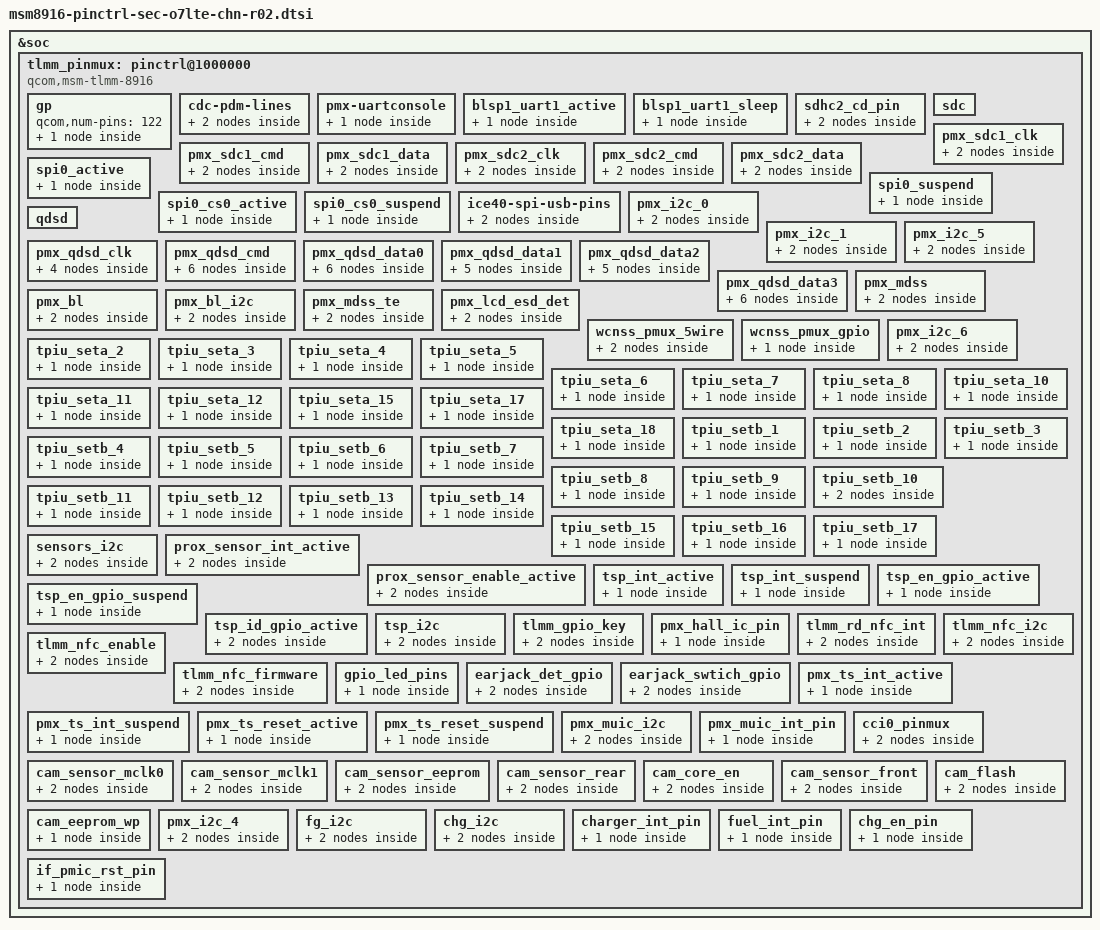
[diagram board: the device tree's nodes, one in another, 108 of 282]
/* Copyright (c) 2013-2014, The Linux Foundation. All rights reserved.
 *
 * This program is free software; you can redistribute it and/or modify
 * it under the terms of the GNU General Public License version 2 and
 * only version 2 as published by the Free Software Foundation.
 *
 * This program is distributed in the hope that it will be useful,
 * but WITHOUT ANY WARRANTY; without even the implied warranty of
 * MERCHANTABILITY or FITNESS FOR A PARTICULAR PURPOSE.  See the
 * GNU General Public License for more details.
 */

&soc {
	tlmm_pinmux: pinctrl@1000000 {
		compatible = "qcom,msm-tlmm-8916";
		reg = <0x1000000 0x300000>;
		interrupts = <0 208 0>;

		/*General purpose pins*/
		gp: gp {
			qcom,num-pins = <122>;
			#qcom,pin-cells = <1>;
			msm_gpio: msm_gpio {
				compatible = "qcom,msm-tlmm-gp";
				gpio-controller;
				#gpio-cells = <2>;
				interrupt-controller;
				#interrupt-cells = <2>;
				num_irqs = <122>;
			};
		};

		cdc-pdm-lines {
			qcom,pins = <&gp 63>, <&gp 64>, <&gp 65>,
					<&gp 66>, <&gp 67>, <&gp 68>;
			qcom,num-grp-pins = <6>;
			qcom,pin-func = <1>;
			label = "cdc-pdm-lines";
			cdc_pdm_lines_act: pdm_lines_on {
				drive-strength = <8>;
				bias-pull-down;
			};
			cdc_pdm_lines_sus: pdm_lines_off {
				drive-strength = <2>;
				bias-pull-down;
			};
		};
		pmx-uartconsole {
			qcom,pins = <&gp 4>, <&gp 5>;
			qcom,num-grp-pins = <2>;
			qcom,pin-func = <2>;
			label = "uart-console";

		uart_console_sleep: uart-console {
				drive-strength = <2>;
				bias-pull-down;
			};
		};

		blsp1_uart1_active {
			qcom,pins = <&gp 0>, <&gp 1>, <&gp 2>, <&gp 3>;
			qcom,num-grp-pins = <4>;
			qcom,pin-func = <2>;
		        label = "blsp1_uart1_active";

			hsuart_active: default {
				drive-strength = <16>;
				bias-disable;
			};
		};

		blsp1_uart1_sleep {
			qcom,pins = <&gp 0>, <&gp 1>, <&gp 2>, <&gp 3>;
			qcom,num-grp-pins = <4>;
			qcom,pin-func = <0>;
		        label = "blsp1_uart1_sleep";

			hsuart_sleep: sleep {
				drive-strength = <2>;
				bias-disable;
			};
		};


		sdhc2_cd_pin {
			qcom,pins = <&gp 38>;
			qcom,num-grp-pins = <1>;
			qcom,pin-func = <0>;
			label = "cd-gpio";
			sdc2_cd_on: cd_on {
				drive-strength = <2>;
				bias-disable;
			};
			sdc2_cd_off: cd_off {
				drive-strength = <2>;
				bias-disable;
			};
		};

		/* SDC pin type */
		sdc: sdc {
			qcom,pin-type-sdc;
			/* 0-2 for sdc1 4-6 for sdc2 */
			qcom,num-pins = <7>;
			/* Order of pins */
			/* SDC1: CLK -> 0, CMD -> 1, DATA -> 2 */
			/* SDC2: CLK -> 4, CMD -> 5, DATA -> 6 */
			#qcom,pin-cells = <1>;
		};

		pmx_sdc1_clk {
			qcom,pins = <&sdc 0>;
			qcom,num-grp-pins = <1>;
			label = "sdc1-clk";
			sdc1_clk_on: clk_on {
				bias-disable; /* NO pull */
				drive-strength = <16>; /* 16 MA */
			};
			sdc1_clk_off: clk_off {
				bias-disable; /* NO pull */
				drive-strength = <2>; /* 2 MA */
			};
		};

		pmx_sdc1_cmd {
			qcom,pins = <&sdc 1>;
			qcom,num-grp-pins = <1>;
			label = "sdc1-cmd";
			sdc1_cmd_on: cmd_on {
				bias-pull-up; /* pull up */
				drive-strength = <10>; /* 10 MA */
			};
			sdc1_cmd_off: cmd_off {
				bias-pull-up; /* pull up */
				drive-strength = <2>; /* 2 MA */
			};
		};

		pmx_sdc1_data {
			qcom,pins = <&sdc 2>;
			qcom,num-grp-pins = <1>;
			label = "sdc1-data";
			sdc1_data_on: data_on {
				bias-pull-up; /* pull up */
				drive-strength = <10>; /* 10 MA */
			};
			sdc1_data_off: data_off {
				bias-pull-up; /* pull up */
				drive-strength = <2>; /* 2 MA */
			};
		};

		pmx_sdc2_clk {
			qcom,pins = <&sdc 4>;
			qcom,num-grp-pins = <1>;
			label = "sdc2-clk";
			sdc2_clk_on: clk_on {
				bias-disable; /* NO pull */
				drive-strength = <16>; /* 16 MA */
			};
			sdc2_clk_off: clk_off {
				bias-disable; /* NO pull */
				drive-strength = <2>; /* 2 MA */
			};
		};

		pmx_sdc2_cmd {
			qcom,pins = <&sdc 5>;
			qcom,num-grp-pins = <1>;
			label = "sdc2-cmd";
			sdc2_cmd_on: cmd_on {
				bias-pull-up; /* pull up */
				drive-strength = <8>; /* 8 MA */
			};
			sdc2_cmd_off: cmd_off {
				bias-pull-up; /* pull up */
				drive-strength = <2>; /* 2 MA */
			};
		};

		pmx_sdc2_data {
			qcom,pins = <&sdc 6>;
			qcom,num-grp-pins = <1>;
			label = "sdc2-data";
			sdc2_data_on: data_on {
				bias-pull-up; /* pull up */
				drive-strength = <8>; /* 8 MA */
			};
			sdc2_data_off: data_off {
				bias-pull-up; /* pull up */
				drive-strength = <2>; /* 2 MA */
			};
		};

               spi0_active {
                        /* MOSI, MISO, CLK */
                        qcom,pins = <&gp 8>, <&gp 9>, <&gp 11>;
                        qcom,num-grp-pins = <3>;
                        qcom,pin-func = <1>;
                        label = "spi0-active";
                        /* active state */
                        spi0_default: default {
                                drive-strength = <12>; /* 12 MA */
                                bias-disable = <0>; /* No PULL */
                        };
                };

                spi0_suspend {
                        /* MOSI, MISO, CLK */
                        qcom,pins = <&gp 8>, <&gp 9>, <&gp 11>;
                        qcom,num-grp-pins = <3>;
                        qcom,pin-func = <0>;
                        label = "spi0-suspend";
                        /* suspended state */
                        spi0_sleep: sleep {
                                drive-strength = <2>; /* 2 MA */
                               bias-pull-down; /* pull down */
                        };
                };

                spi0_cs0_active {
                        /* CS */
                        qcom,pins = <&gp 10>;
                        qcom,num-grp-pins = <1>;
                        qcom,pin-func = <1>;
                        label = "spi0-cs0-active";
                        spi0_cs0_active: cs0_active {
                                drive-strength = <2>;
                                bias-disable = <0>;
                        };
                };

                spi0_cs0_suspend {
                        /* CS */
                        qcom,pins = <&gp 10>;
                        qcom,num-grp-pins = <1>;
                        qcom,pin-func = <0>;
                        label = "spi0-cs0-suspend";
                        spi0_cs0_sleep: cs0_sleep {
                                drive-strength = <2>;
                                bias-disable = <0>;
                        };
                };

                ice40-spi-usb-pins {
                        qcom,pins = <&gp 0>, <&gp 1>, <&gp 3>;
                        qcom,num-grp-pins = <3>;
                        qcom,pin-func = <0>;
                        label = "ice40-spi-usb-pins";

                        /* active state */
                        ice40_default: default {
                                drive-strength = <8>;
                                bias-disable;
                        };

                        /* sleep state */
                        ice40_sleep: sleep {
                                drive-strength = <2>;
                                bias-pull-down;
                        };
                };

		pmx_i2c_0 {
			/* CLK, DATA */
			qcom,pins = <&gp 7>, <&gp 6>;
			qcom,num-grp-pins = <2>;
			qcom,pin-func = <3>;
			label = "pmx_i2c_0";

			i2c_0_active: i2c_0_active {
				drive-strength = <2>; /* 2 MA */
				bias-disable;         /* No PULL */
			};

			i2c_0_sleep: i2c_0_sleep {
				drive-strength = <2>; /* 2 MA */
				bias-disable;	      /* No PULL */
			};
		};

		pmx_i2c_1 {
			/* CLK, DATA */
			qcom,pins = <&gp 3>, <&gp 2>;
			qcom,num-grp-pins = <2>;
			qcom,pin-func = <3>;
			label = "pmx_i2c_1";

			i2c_1_active: i2c_1_active {
				drive-strength = <2>; /* 2 MA */
				bias-pull-down;         /* PULL DOWN */
			};

			i2c_1_sleep: i2c_1_sleep {
				drive-strength = <2>; /* 2 MA */
				bias-pull-down;	      /* PULL DOWN */
			};
		};

		pmx_i2c_5 {
			/* CLK, DATA */
			qcom,pins = <&gp 19>, <&gp 18>;
			qcom,num-grp-pins = <2>;
			qcom,pin-func = <2>;
			label = "pmx_i2c_5";

			i2c_5_active: i2c_5_active {
				drive-strength = <2>; /* 2 MA */
				bias-disable = <0>; /* No PULL */
			};

			i2c_5_sleep: i2c_5_sleep {
				drive-strength = <2>; /* 2 MA */
				bias-disable = <0>; /* No PULL */
			};
		};

		/* QDSD pin type */
		qdsd: qdsd {
			qcom,pin-type-qdsd;
			/* 0-> clk, 1 -> cmd, 2->data0, 3->data1, 4->data2, 5->data3 */
			qcom,num-pins = <6>;

			#qcom,pin-cells = <1>;
		};

		pmx_qdsd_clk {
			qcom,pins = <&qdsd 0>;
			qcom,num-grp-pins = <1>;
			label = "qdsd-clk";
			qdsd_clk_sdcard: clk_sdcard {
				bias-disable; /* NO pull */
				drive-strength = <7>; /* 7 MA */
			};
			qdsd_clk_trace: clk_trace {
				bias-pull-down; /* pull down */
				drive-strength = <0>; /* 0 MA */
			};
			qdsd_clk_swdtrc: clk_swdtrc {
				bias-pull-down; /* pull down */
				drive-strength = <0>; /* 0 MA */
			};
			qdsd_clk_spmi: clk_spmi {
				bias-pull-down; /* pull down */
				drive-strength = <0>; /* 0 MA */
			};
		};

		pmx_qdsd_cmd {
			qcom,pins = <&qdsd 1>;
			qcom,num-grp-pins = <1>;
			label = "qdsd-cmd";
			qdsd_cmd_sdcard: cmd_sdcard {
				bias-pull-down; /* pull down */
				drive-strength = <3>; /* 3 MA */
			};
			qdsd_cmd_trace: cmd_trace {
				bias-pull-down; /* pull down */
				drive-strength = <0>; /* 0 MA */
			};
			qdsd_cmd_swduart: cmd_uart {
				bias-pull-up; /* pull up */
				drive-strength = <0>; /* 0 MA */
			};
			qdsd_cmd_swdtrc: cmd_swdtrc {
				bias-pull-up; /* pull up */
				drive-strength = <0>; /* 0 MA */
			};
			qdsd_cmd_jtag: cmd_jtag {
				bias-disable; /* NO pull */
				drive-strength = <3>; /* 3 MA */
			};
			qdsd_cmd_spmi: cmd_spmi {
				bias-pull-down; /* pull down */
				drive-strength = <4>; /* 4 MA */
			};
		};

		pmx_qdsd_data0 {
			qcom,pins = <&qdsd 2>;
			qcom,num-grp-pins = <1>;
			label = "qdsd-data0";
			qdsd_data0_sdcard: data0_sdcard {
				bias-pull-down; /* pull down */
				drive-strength = <3>; /* 3 MA */
			};
			qdsd_data0_trace: data0_trace {
				bias-pull-down; /* pull down */
				drive-strength = <0>; /* 0 MA */
			};
			qdsd_data0_swduart: data0_uart {
				bias-pull-down; /* pull down */
				drive-strength = <0>; /* 0 MA */
			};
			qdsd_data0_swdtrc: data0_swdtrc {
				bias-pull-down; /* pull down */
				drive-strength = <0>; /* 0 MA */
			};
			qdsd_data0_jtag: data0_jtag {
				bias-pull-up; /* pull up */
				drive-strength = <0>; /* 0 MA */
			};
			qdsd_data0_spmi: data0_spmi {
				bias-pull-down; /* pull down */
				drive-strength = <0>; /* 0 MA */
			};
		};

		pmx_qdsd_data1 {
			qcom,pins = <&qdsd 3>;
			qcom,num-grp-pins = <1>;
			label = "qdsd-data1";
			qdsd_data1_sdcard: data1_sdcard {
				bias-pull-down; /* pull down */
				drive-strength = <3>; /* 3 MA */
			};
			qdsd_data1_trace: data1_trace {
				bias-pull-down; /* pull down */
				drive-strength = <0>; /* 0 MA */
			};
			qdsd_data1_swduart: data1_uart {
				bias-pull-down; /* pull down */
				drive-strength = <0>; /* 0 MA */
			};
			qdsd_data1_swdtrc: data1_swdtrc {
				bias-pull-down; /* pull down */
				drive-strength = <0>; /* 0 MA */
			};
			qdsd_data1_jtag: data1_jtag {
				bias-pull-down; /* pull down */
				drive-strength = <0>; /* 0 MA */
			};
		};

		pmx_qdsd_data2 {
			qcom,pins = <&qdsd 4>;
			qcom,num-grp-pins = <1>;
			label = "qdsd-data2";
			qdsd_data2_sdcard: data2_sdcard {
				bias-pull-down; /* pull down */
				drive-strength = <3>; /* 3 MA */
			};
			qdsd_data2_trace: data2_trace {
				bias-pull-down; /* pull down */
				drive-strength = <0>; /* 0 MA */
			};
			qdsd_data2_swduart: data2_uart {
				bias-pull-down; /* pull down */
				drive-strength = <0>; /* 0 MA */
			};
			qdsd_data2_swdtrc: data2_swdtrc {
				bias-pull-down; /* pull down */
				drive-strength = <0>; /* 0 MA */
			};
			qdsd_data2_jtag: data2_jtag {
				bias-pull-up; /* pull up */
				drive-strength = <3>; /* 3 MA */
			};
		};

		pmx_qdsd_data3 {
			qcom,pins = <&qdsd 5>;
			qcom,num-grp-pins = <1>;
			label = "qdsd-data3";
			qdsd_data3_sdcard: data3_sdcard {
				bias-pull-down; /* pull down */
				drive-strength = <3>; /* 3 MA */
			};
			qdsd_data3_trace: data3_trace {
				bias-pull-down; /* pull down */
				drive-strength = <0>; /* 0 MA */
			};
			qdsd_data3_swduart: data3_uart {
				bias-pull-up; /* pull up */
				drive-strength = <0>; /* 0 MA */
			};
			qdsd_data3_swdtrc: data3_swdtrc {
				bias-pull-up; /* pull up */
				drive-strength = <0>; /* 0 MA */
			};
			qdsd_data3_jtag: data3_jtag {
				bias-pull-up; /* pull up */
				drive-strength = <0>; /* 0 MA */
			};
			qdsd_data3_spmi: data3_spmi {
				bias-pull-down; /* pull down */
				drive-strength = <3>; /* 3 MA */
			};
		};

		pmx_mdss: pmx_mdss {
			label = "mdss-pins";
			qcom,num-grp-pins = <1>;
			qcom,pins = <&gp 25>;
			qcom,pin-func = <0>;
			mdss_dsi_active: active {
				drive-strength = <2>; /* 2 mA */
				bias-disable = <0>; /* no pull */
			};
			mdss_dsi_suspend: suspend {
				drive-strength = <2>; /* 2 mA */
				bias-pull-down; /* pull down */
				output-low;
			};
		};

		pmx_bl: pmx_bl {
			label = "bl-pins";
			qcom,num-grp-pins = <4>;
			qcom,pins = <&gp 97>, <&gp 120>, <&gp 98>, <&gp 16>;
			qcom,pin-func = <0>;
			bl_active: active {
				drive-strength = <2>; /* 2 mA */
				bias-disable = <0>; /* no pull */
			};
			bl_suspend: suspend {
				drive-strength = <2>; /* 2 mA */
				bias-disable = <0>; /* no pull */
				output-low;
			};
		};

		pmx_bl_i2c: pmx_bl_i2c {
			label = "bl-pins";
			qcom,num-grp-pins = <2>;
			qcom,pins = <&gp 101>, <&gp 102>;
			qcom,pin-func = <0>;
			bl_i2c_active: active {
				drive-strength = <2>; /* 2 mA */
				bias-disable = <0>; /* no pull */
			};
			bl_i2c_suspend: suspend {
				drive-strength = <2>; /* 2 mA */
				bias-disable = <0>; /* no pull */
			};
		};

		pmx_mdss_te: pmx_mdss_te {
			label = "mdss-te-pin";
			qcom,pin-func = <1>;
			mdss_te_active: active {
				drive-strength = <2>; /* 2 mA */
				bias-pull-down; /* pull down */
				input-debounce = <0>;
			};
			mdss_te_suspend: suspend {
				drive-strength = <2>; /* 2 mA */
				bias-pull-down; /* pull down */
				input-debounce = <0>;
			};
		};

		pmx_lcd_esd_det: pmx_lcd_esd_det {
			qcom,num-grp-pins = <1>;
			qcom,pins = <&gp 69>;
			qcom,pin-func = <0>;
			label = "lcd-esd-det-pin";
			lcd_esd_det_active: active {
				drive-strength = <2>;
				bias-disable = <0>; /* no pull */
			};
			lcd_esd_det_suspend: suspend {
				drive-strength = <2>;
				bias-disable = <0>; /* no pull */
			};
		};

		wcnss_pmux_5wire: wcnss_pmux_5wire {
			/* Uses general purpose pins */
			qcom,pins = <&gp 40>, <&gp 41>,
				    <&gp 42>, <&gp 43>,
				    <&gp 44>;
			qcom,num-grp-pins = <5>;
			qcom,pin-func = <1>;
			label = "wcnss_5wire_pins";
			/* Active configuration of bus pins */
			wcnss_default: wcnss_default {
			        drive-strength = <6>; /* 6 MA */
			        bias-pull-up; /* PULL UP */
			};
			wcnss_sleep: wcnss_sleep {
			        drive-strength = <2>; /* 2 MA */
			        bias-pull-down; /* PULL Down */
			};
		};

		wcnss_pmux_gpio: wcnss_pmux_gpio {
			/* Uses general purpose pins */
			qcom,pins = <&gp 40>, <&gp 41>,
				    <&gp 42>, <&gp 43>,
				    <&gp 44>;
			qcom,num-grp-pins = <5>;
			qcom,pin-func = <0>;
			label = "wcnss_5gpio_pins";
			/* Active configuration of bus pins */
			wcnss_gpio_default: wcnss_gpio_default {
			        drive-strength = <6>; /* 6 MA */
			        bias-pull-up; /* PULL UP */
			};
		};

		pmx_i2c_6 {
			/* CLK, DATA */
			qcom,pins = <&gp 22>, <&gp 23>;
			qcom,num-grp-pins = <2>;
			qcom,pin-func = <2>;
			label = "pmx_i2c_6";
			/* active state */
			i2c_6_active: i2c_6_active{
				drive-strength = <2>; /* 2 MA */
				bias-disable; /* No PULL */
			};
			/*suspended state */
			i2c_6_sleep: i2c_6_sleep {
				drive-strength = <2>; /* 2 MA */
				bias-disable; /* No PULL */
			};
		};

		/* CoreSight */
		/*tpiu_seta_1 {
			qcom,pins = <&gp 8>;
			qcom,num-grp-pins = <1>;
			qcom,pin-func = <3>;
			label = "tpiu-seta-1";
			seta_1: seta {
				drive-strength = <16>;
				bias-disable;
			};
		};*/

		tpiu_seta_2 {
			qcom,pins = <&gp 9>;
			qcom,num-grp-pins = <1>;
			qcom,pin-func = <2>;
			label = "tpiu-seta-2";
			seta_2: seta {
				drive-strength = <16>;
				bias-disable;
			};
		};

		tpiu_seta_3 {
			qcom,pins = <&gp 10>;
			qcom,num-grp-pins = <1>;
			qcom,pin-func = <3>;
			label = "tpiu-seta-3";
			seta_3: seta {
				drive-strength = <16>;
				bias-disable;
			};
		};

		tpiu_seta_4 {
			qcom,pins = <&gp 39>;
			qcom,num-grp-pins = <1>;
			qcom,pin-func = <2>;
			label = "tpiu-seta-4";
			seta_4: seta {
				drive-strength = <16>;
				bias-disable;
			};
		};

		tpiu_seta_5 {
			qcom,pins = <&gp 40>;
			qcom,num-grp-pins = <1>;
			qcom,pin-func = <2>;
			label = "tpiu-seta-5";
			seta_5: seta {
				drive-strength = <16>;
				bias-disable;
			};
		};

		tpiu_seta_6 {
			qcom,pins = <&gp 41>;
			qcom,num-grp-pins = <1>;
			qcom,pin-func = <2>;
			label = "tpiu-seta-6";
			seta_6: seta {
				drive-strength = <16>;
				bias-disable;
			};
		};

		tpiu_seta_7 {
			qcom,pins = <&gp 42>;
			qcom,num-grp-pins = <1>;
			qcom,pin-func = <2>;
			label = "tpiu-seta-7";
			seta_7: seta {
				drive-strength = <16>;
				bias-disable;
			};
		};

		tpiu_seta_8 {
			qcom,pins = <&gp 43>;
			qcom,num-grp-pins = <1>;
			qcom,pin-func = <3>;
			label = "tpiu-seta-8";
			seta_8: seta {
				drive-strength = <16>;
				bias-disable;
			};
		};

		/*tpiu_seta_9 {
			qcom,pins = <&gp 45>;
			qcom,num-grp-pins = <1>;
			qcom,pin-func = <0>;
			label = "tpiu-seta-9";
			seta_9: seta {
				drive-strength = <16>;
				bias-pull-up;
			};
		};*/

		tpiu_seta_10 {
			qcom,pins = <&gp 46>;
			qcom,num-grp-pins = <1>;
			qcom,pin-func = <2>;
			label = "tpiu-seta-10";
			seta_10: seta {
				drive-strength = <16>;
				bias-disable;
			};
		};

		tpiu_seta_11 {
			qcom,pins = <&gp 47>;
			qcom,num-grp-pins = <1>;
			qcom,pin-func = <3>;
			label = "tpiu-seta-11";
			seta_11: seta {
				drive-strength = <16>;
				bias-disable;
			};
		};

		tpiu_seta_12 {
			qcom,pins = <&gp 48>;
			qcom,num-grp-pins = <1>;
			qcom,pin-func = <2>;
			label = "tpiu-seta-12";
			seta_12: seta {
				drive-strength = <16>;
				bias-disable;
			};
		};
/*
		tpiu_seta_13 {
			qcom,pins = <&gp 62>;
			qcom,num-grp-pins = <1>;
			qcom,pin-func = <2>;
			label = "tpiu-seta-13";
			seta_13: seta {
				drive-strength = <16>;
				bias-disable;
			};
		};
*/
		tpiu_seta_15 {
			qcom,pins = <&gp 112>;
			qcom,num-grp-pins = <1>;
			qcom,pin-func = <5>;
			label = "tpiu-seta-15";
			seta_15: seta {
				drive-strength = <16>;
				bias-disable;
			};
		};
/*
		tpiu_seta_16 {
			qcom,pins = <&gp 113>;
			qcom,num-grp-pins = <1>;
			qcom,pin-func = <9>;
			label = "tpiu-seta-16";
			seta_16: seta {
				drive-strength = <16>;
				bias-disable;
			};
		};
*/
		tpiu_seta_17 {
			qcom,pins = <&gp 114>;
			qcom,num-grp-pins = <1>;
			qcom,pin-func = <8>;
			label = "tpiu-seta-17";
			seta_17: seta {
				drive-strength = <16>;
				bias-disable;
			};
		};

		tpiu_seta_18 {
			qcom,pins = <&gp 115>;
			qcom,num-grp-pins = <1>;
			qcom,pin-func = <8>;
			label = "tpiu-seta-18";
			seta_18: seta {
				drive-strength = <16>;
				bias-disable;
			};
		};

		tpiu_setb_1 {
			qcom,pins = <&gp 4>;
			qcom,num-grp-pins = <1>;
			qcom,pin-func = <5>;
			label = "tpiu-setb-1";
			setb_1: setb {
				drive-strength = <16>;
				bias-disable;
			};
		};

		tpiu_setb_2 {
			qcom,pins = <&gp 5>;
			qcom,num-grp-pins = <1>;
			qcom,pin-func = <5>;
			label = "tpiu-setb-2";
			setb_2: setb {
				drive-strength = <16>;
				bias-disable;
			};
		};

		tpiu_setb_3 {
			qcom,pins = <&gp 26>;
			qcom,num-grp-pins = <1>;
			qcom,pin-func = <7>;
			label = "tpiu-setb-3";
			setb_3: setb {
				drive-strength = <16>;
				bias-disable;
			};
		};

		tpiu_setb_4 {
			qcom,pins = <&gp 27>;
			qcom,num-grp-pins = <1>;
			qcom,pin-func = <9>;
			label = "tpiu-setb-4";
			setb_4: setb {
				drive-strength = <16>;
				bias-disable;
			};
		};

		tpiu_setb_5 {
			qcom,pins = <&gp 28>;
			qcom,num-grp-pins = <1>;
			qcom,pin-func = <7>;
			label = "tpiu-setb-5";
			setb_5: setb {
				drive-strength = <16>;
				bias-disable;
			};
		};

		tpiu_setb_6 {
			qcom,pins = <&gp 29>;
			qcom,num-grp-pins = <1>;
			qcom,pin-func = <7>;
			label = "tpiu-setb-6";
			setb_6: setb {
				drive-strength = <16>;
				bias-disable;
			};
		};

		tpiu_setb_7 {
			qcom,pins = <&gp 30>;
			qcom,num-grp-pins = <1>;
			qcom,pin-func = <9>;
			label = "tpiu-setb-7";
			setb_7: setb {
				drive-strength = <16>;
				bias-disable;
			};
		};

		tpiu_setb_8 {
			qcom,pins = <&gp 31>;
			qcom,num-grp-pins = <1>;
			qcom,pin-func = <10>;
			label = "tpiu-setb-8";
			setb_8: setb {
				drive-strength = <16>;
				bias-disable;
			};
		};

		tpiu_setb_9 {
			qcom,pins = <&gp 32>;
			qcom,num-grp-pins = <1>;
			qcom,pin-func = <10>;
			label = "tpiu-setb-9";
			setb_9: setb {
				drive-strength = <16>;
				bias-disable;
			};
		};

		tpiu_setb_10 {
			qcom,pins = <&gp 33>;
			qcom,num-grp-pins = <1>;
			qcom,pin-func = <0>;
			label = "tpiu-setb-10";
			/*setb_10: setb {
				drive-strength = <16>;
				bias-disable;
			};*/

			setb_10_default: default  {
				drive-strength = <16>;
				bias-disable;
			};

			setb_10_sleep: sleep  {
				bias-pull-down;
				output-low;
			};
		};

		tpiu_setb_11 {
			qcom,pins = <&gp 34>;
			qcom,num-grp-pins = <1>;
			qcom,pin-func = <9>;
			label = "tpiu-setb-11";
			setb_11: setb {
				drive-strength = <16>;
				bias-disable;
			};
		};

		tpiu_setb_12 {
			qcom,pins = <&gp 35>;
			qcom,num-grp-pins = <1>;
			qcom,pin-func = <9>;
			label = "tpiu-setb-12";
			setb_12: setb {
				drive-strength = <16>;
				bias-disable;
			};
		};

		tpiu_setb_13 {
			qcom,pins = <&gp 36>;
			qcom,num-grp-pins = <1>;
			qcom,pin-func = <8>;
			label = "tpiu-setb-13";
			setb_13: setb {
				drive-strength = <16>;
				bias-disable;
			};
		};

		tpiu_setb_14 {
			qcom,pins = <&gp 37>;
			qcom,num-grp-pins = <1>;
			qcom,pin-func = <7>;
			label = "tpiu-setb-14";
			setb_14: setb {
				drive-strength = <16>;
				bias-disable;
			};
		};

		tpiu_setb_15 {
			qcom,pins = <&gp 110>;
			qcom,num-grp-pins = <1>;
			qcom,pin-func = <4>;
			label = "tpiu-setb-15";
			setb_15: setb {
				drive-strength = <16>;
				bias-disable;
			};
		};

		tpiu_setb_16 {
			qcom,pins = <&gp 111>;
			qcom,num-grp-pins = <1>;
			qcom,pin-func = <1>;
			label = "tpiu-setb-16";
			setb_16: setb {
				drive-strength = <16>;
				bias-disable;
			};
		};

		tpiu_setb_17 {
			qcom,pins = <&gp 120>;
			qcom,num-grp-pins = <1>;
			qcom,pin-func = <10>;
			label = "tpiu-setb-17";
			setb_17: setb {
				drive-strength = <16>;
				bias-disable;
			};
		};
/*
		tpiu_setb_18 {
			qcom,pins = <&gp 121>;
			qcom,num-grp-pins = <1>;
			qcom,pin-func = <11>;
			label = "tpiu-setb-18";
			setb_18: setb {
				drive-strength = <16>;
				bias-disable;
			};
		};
*/
		sensors_i2c{
			qcom,pins = <&gp 31>, <&gp 32>;
			qcom,pin-func = <0>;
			qcom,num-grp-pins = <2>;
			label = "sensors_i2c";
			sensors_i2c_active: sensors_i2c_active {
				drive-strength = <2>;
				bias-disable; /* No PULL */
			};
			sensors_i2c_suspend: sensors_i2c_suspend {
				drive-strength = <2>;
				bias-disable; /* No PULL */
			};
		};

		/* add pingrp for proximity sensors  */
		prox_sensor_int_active {
			qcom,pins = <&gp 113>;
			qcom,pin-func = <0>;
			qcom,num-grp-pins = <1>;
			label = "prox_sensor_int_active";
			prox_int_active: prox_int_active {
				drive-strength = <2>;
				bias-disable; /* No PULL */
			};
			prox_int_suspend: prox_int_suspend {
				drive-strength = <2>;
				bias-disable; /* No PULL */
			};
		};

		prox_sensor_enable_active {
			qcom,pins = <&gp 8>;
			qcom,pin-func = <0>;
			qcom,num-grp-pins = <1>;
			label = "prox_sensor_enable_active";
			prox_enable_active: prox_enable_active {
				drive-strength = <2>;
				bias-disable; /* No PULL */
			};
			prox_enable_suspend: prox_enable_suspend {
				drive-strength = <2>;
				bias-disable; /* No PULL */
			};
		};

		tsp_int_active {
			qcom,pins = <&gp 13>;
			qcom,num-grp-pins = <1>;
			qcom,pin-func = <0>;
			label = "tsp_int_active";
			int_active: int_active {
				drive-strength = <2>;
				bias-disable; /* No PULL */
			};
		};

		tsp_int_suspend {
			qcom,pins = <&gp 13>;
			qcom,num-grp-pins = <1>;
			qcom,pin-func = <0>;
			label = "tsp_int_suspend";
			int_suspend: int_suspend {
				drive-strength = <2>;
				bias-disable; /* No PULL */
			};
		};

		tsp_en_gpio_active {
			qcom,pins = <&gp 8>;
			qcom,num-grp-pins = <1>;
			qcom,pin-func = <0>;
			label = "tsp_en_gpio_active";
			tsp_en_active: tsp_en_active {
				drive-strength = <2>;
				bias-disable; /* No PULL */
			};
		};

		tsp_en_gpio_suspend {
			qcom,pins = <&gp 8>;
			qcom,num-grp-pins = <1>;
			qcom,pin-func = <0>;
			label = "tsp_en_gpio_suspend";
			tsp_en_suspend: tsp_en_suspend {
				drive-strength = <2>;
				bias-disable; /* No PULL */
			};
		};

		tsp_id_gpio_active {
			qcom,pins = <&gp 56>;
			qcom,num-grp-pins = <1>;
			qcom,pin-func = <0>;
			label = "tsp_id_gpio_active";
			tsp_id_active: tsp_id_active {
				drive-strength = <2>;
				bias-disable; /* No PULL */
			};

			tsp_id_suspend: tsp_id_suspend {
				drive-strength = <2>;
				bias-disable; /* No PULL */
			};
		};

		tsp_i2c {
			/* CLK, DATA */
			qcom,pins = <&gp 19>, <&gp 18>;
			qcom,num-grp-pins = <2>;
			qcom,pin-func = <0>;
			label = "tsp_i2c";

			tsp_i2c_active: tsp_i2c_active {
				drive-strength = <2>; /* 2 MA */
				bias-disable = <0>; /* No PULL */
			};

			tsp_i2c_sleep: tsp_i2c_sleep {
				drive-strength = <2>; /* 2 MA */
				bias-disable = <0>; /* No PULL */
			};
		};

		tlmm_gpio_key {
			qcom,pins = <&gp 107>, <&gp 109>;
			qcom,pin-func = <0>;
			qcom,num-grp-pins = <2>;
			label = "tlmm_gpio_key";
			gpio_key_active: gpio_key_active {
				drive-strength = <2>;
				bias-pull-up;
			};
			gpio_key_suspend: gpio_key_suspend {
				drive-strength = <2>;
				bias-pull-up;
			};
		};

		/*Hall IC pingroup*/
		pmx_hall_ic_pin {
			qcom,pins = <&gp 112>;
			qcom,pin-func = <0>;
			qcom,num-grp-pins = <1>;
			label = "pmx_hall_ic_pin";

			hall_ic_pin: default {
				drive-strength = <2>;
				bias-disable;
			};
		};

		tlmm_rd_nfc_int{
			qcom,pins = <&gp 21>;
			qcom,pin-func = <0>;
			qcom,num-grp-pins = <1>;
			label = "tlmm_rd_nfc_int";

			nfc_int_active: nfc_int_active {
				drive-strength = <2>;
				bias-pull-down;
			};

			nfc_int_suspend: nfc_int_suspend {
				drive-strength = <2>;
				bias-pull-down;
			};
		};

		tlmm_nfc_enable{
			qcom,pins = <&gp 20>;
			qcom,pin-func = <0>;
			qcom,num-grp-pins = <1>;
			label = "tlmm_nfc_enable";

			nfc_enable_active: nfc_enable_active {
				drive-strength = <2>;
				bias-pull-up;
			};

			nfc_enable_suspend: nfc_enable_suspend {
				drive-strength = <2>;
				bias-pull-up;
			};
		};

		tlmm_nfc_firmware{
			qcom,pins = <&gp 49>;
			qcom,pin-func = <0>;
			qcom,num-grp-pins = <1>;
			label = "tlmm_nfc_firmware";

			nfc_firmware_active: nfc_firmware_active {
				drive-strength = <2>;
				bias-pull-down;
			};

			nfc_firmware_suspend: nfc_firmware_suspend {
				drive-strength = <2>;
				bias-pull-down;
			};
		};

		tlmm_nfc_i2c{
			qcom,pins = <&gp 0>, <&gp 1>;
			qcom,pin-func = <0>;
			qcom,num-grp-pins = <2>;
			label = "tlmm_nfc_i2c";

			nfc_i2c_active: nfc_i2c_active {
				drive-strength = <2>;
				bias-disable;
			};

			nfc_i2c_suspend: nfc_i2c_suspend {
				drive-strength = <2>;
				bias-disable;
			};
		};

		gpio_led_pins {
			qcom,pins = <&gp 9>;
			qcom,num-grp-pins = <1>;
			label = "gpio-led-pins";
			gpio_led_off: led_off {
				drive-strength = <2>;
				bias-disable;
				output-low;
			};
		};

		earjack_det_gpio {
			qcom,pins = <&gp 110>;
			qcom,pin-func = <0>;
			qcom,num-grp-pins = <1>;
			label = "earjack_det_gpio";
			earjack_det_act: earjack_det_act {
				drive-strength = <2>;
				bias-disable;
			};
			earjack_det_sus: earjack_det_sus {
				drive-strength = <2>;
				bias-disable;
			};
		};
		earjack_swtich_gpio {
			qcom,pins = <&gp 111>;
			qcom,pin-func = <0>;
			qcom,num-grp-pins = <1>;
			label = "earjack_swtich_gpio";
			earjack_switch_act: earjack_switch_act {
				drive-strength = <2>;
				bias-disable;
			};
			earjack_switch_sus: earjack_switch_sus {
				drive-strength = <2>;
				bias-disable;
			};
		};

		/* add pingrp for touchscreen */
		pmx_ts_int_active {
			qcom,pins = <&gp 18>;
			qcom,pin-func = <3>;
			qcom,num-grp-pins = <1>;
			label = "pmx_ts_int_active";

			ts_int_active: ts_int_active {
				drive-strength = <16>;
				bias-pull-up;
			};
		};

		pmx_ts_int_suspend {
			qcom,pins = <&gp 18>;
			qcom,pin-func = <3>;
			qcom,num-grp-pins = <1>;
			label = "pmx_ts_int_suspend";

			ts_int_suspend: ts_int_suspend {
				drive-strength = <2>;
				bias-pull-down;
			};
		};

		pmx_ts_reset_active {
			qcom,pins = <&gp 19>;
			qcom,pin-func = <3>;
			qcom,num-grp-pins = <1>;
			label = "pmx_ts_reset_active";

			ts_reset_active: ts_reset_active {
				drive-strength = <16>;
				bias-pull-up;
			};
		};

		pmx_ts_reset_suspend {
			qcom,pins = <&gp 19>;
			qcom,pin-func = <3>;
			qcom,num-grp-pins = <1>;
			label = "pmx_ts_reset_suspend";

			ts_reset_suspend: ts_reset_suspend {
				drive-strength = <2>;
				bias-pull-down;
			};
		};

		pmx_muic_i2c{
			qcom,pins = <&gp 105>, <&gp 106>;
			qcom,pin-func = <0>;
			qcom,num-grp-pins = <2>;
			label = "pmx_muic_i2c";

			muic_i2c_active: muic_i2c_active {
				drive-strength = <2>;
				bias-disable; /* No PULL */
			};
			muic_i2c_suspend: muic_i2c_suspend {
				drive-strength = <2>;
				bias-disable; /* No PULL */
			};
		};

		/* HOme Key pingroup*/
		/*pmx_home_key_pin {
			qcom,pins = <&gp 109>;
			qcom,pin-func = <0>;
			qcom,num-grp-pins = <1>;
			label = "pmx_home_key_pin";

			home_key_pin: default {
				drive-strength = <2>;
				bias-disable;
			};
		};*/

		/* MUIC INT PIN */
		pmx_muic_int_pin {
			qcom,pins = <&gp 12>;
			qcom,pin-func = <0>;
			qcom,num-grp-pins = <1>;
			label = "pmx_muic_int_pin";

			muic_int_pin: default {
				drive-strength = <2>;
				bias-disable;
			};
		};

		cci0_pinmux {
			/* CLK, DATA */
			qcom,pins = <&gp 29>, <&gp 30>;
			qcom,num-grp-pins = <2>;
			qcom,pin-func = <1>;
			label = "cci0";
			/* active state */
			cci0_default: default {
				drive-strength = <2>; /* 2 MA */
				bias-disable = <0>; /* No PULL */
				input-low;
			};
			/*suspended state */
			cci0_sleep: sleep {
				drive-strength = <2>; /* 2 MA */
				bias-disable = <0>; /* No PULL */
				input-low;
			};
		};

		cam_sensor_mclk0 {
			/* MCLK */
			qcom,pins = <&gp 26>;
			qcom,num-grp-pins = <1>;
			qcom,pin-func = <1>;
			label = "cam-sensor-mclk0";
			/* active state */
			cam_sensor_mclk0_default: default {
				drive-strength = <2>; /* 2 MA */
				bias-pull-down; /* PULL DOWN */
				output-low;
			};
			/*suspended state */
			cam_sensor_mclk0_sleep: sleep {
				drive-strength = <2>; /* 2 MA */
				bias-pull-down; /* PULL DOWN */
				output-low;
			};
		};

		cam_sensor_mclk1 {
			/* MCLK */
			qcom,pins = <&gp 27>;
			qcom,num-grp-pins = <1>;
			qcom,pin-func = <1>;
			label = "cam-sensor-mclk1";
			/* active state */
			cam_sensor_mclk1_default: default {
				drive-strength = <2>; /* 2 MA */
				bias-pull-down; /* PULL DOWN */
				output-low;
			};
			/*suspended state */
			cam_sensor_mclk1_sleep: sleep {
				drive-strength = <2>; /* 2 MA */
				bias-pull-down; /* PULL DOWN */
				output-low;
			};
		};

		cam_sensor_eeprom {
			/* RESET, STANDBY */
			qcom,pins =  <&gp 10>, <&gp 11>;
			qcom,num-grp-pins = <2>;
			qcom,pin-func = <0>;
			label = "cam-eeprom-i2c";
			/* active state */
			cam_sensor_eeprom_default: default {
				drive-strength = <4>; /* 4 MA */
				bias-disable = <0>; /* No PULL */
				input-low;
			};
			/*suspended state */
			cam_sensor_eeprom_sleep: sleep {
				drive-strength = <4>; /* 4 MA */
				bias-disable = <0>; /* No PULL */
				input-low;
			};
		};

		cam_sensor_rear {
			/* RESET, STANDBY */
			qcom,pins =  <&gp 35>;
			qcom,num-grp-pins = <1>;
			qcom,pin-func = <0>;
			label = "cam-sensor-rear";
			/* active state */
			cam_sensor_rear_default: default {
				drive-strength = <2>; /* 2 MA */
				bias-disable = <0>; /* No PULL */
			};
			/*suspended state */
			cam_sensor_rear_sleep: sleep {
				drive-strength = <2>; /* 2 MA */
				bias-pull-down; /* PULL DOWN */
			};
		};

		cam_core_en {
			/* RESET, STANDBY */
			qcom,pins =  <&gp 33>;
			qcom,num-grp-pins = <1>;
			qcom,pin-func = <0>;
			label = "cam_core_en";
			/* active state */
			cam_core_en_default: default {
				drive-strength = <2>; /* 2 MA */
				bias-disable = <0>; /* No PULL */
				output-low;
			};
			/*suspended state */
			cam_core_en_sleep: sleep {
				drive-strength = <2>; /* 2 MA */
				bias-pull-down; /* PULL DOWN */
				output-low;
			};
		};

		cam_sensor_front {
			/* RESET*/
			qcom,pins = <&gp 28>;
			qcom,num-grp-pins = <1>;
			qcom,pin-func = <0>;
			label = "cam_sensor_front";
			/* active state */
			cam_sensor_front_default: default {
				drive-strength = <2>; /* 2 MA */
				bias-disable = <0>; /* No PULL */
			};
			/*suspended state */
			cam_sensor_front_sleep: sleep {
				drive-strength = <2>; /* 2 MA */
				bias-pull-down = <0>; /* PULL DOWN */
			};
		};

		cam_flash {
			qcom,pins = <&gp 34>, <&gp 36>;
			qcom,num-grp-pins = <2>;
			qcom,pin-func = <0>;
			label = "cam_flash";

			cam_flash_active: default {
				drive-strength = <2>;	/* 2 MA */
				bias-pull-down; /* PULL DOWN */
				output-low;
			};

			cam_flash_sleep: sleep {
				drive-strength = <2>;	/* 2 MA */
				bias-pull-down; /* PULL DOWN */
				output-low;
			};
		};

		cam_eeprom_wp {
			/* EEP_WP */
			qcom,pins =  <&gp 9>;
			qcom,num-grp-pins = <1>;
			qcom,pin-func = <0>;
			label = "cam_eeprom_wp";
			/* active state */
			/*suspended state */
			cam_eepwp_sleep: sleep {
				drive-strength = <2>;
				bias-disable;
				output-low;
			};
		};
		pmx_i2c_4 {
			/* CLK, DATA */
			qcom,pins = <&gp 14>, <&gp 15>;
			qcom,num-grp-pins = <2>;
			qcom,pin-func = <2>;
			label = "pmx_i2c_4";

			i2c_4_active: i2c_4_active {
				drive-strength = <2>;	/* 2 MA */
				bias-disable = <0>;	/* No PULL */
			};

			i2c_4_sleep: i2c_4_sleep {
				drive-strength = <2>;	/* 2 MA */
				bias-disable = <0>;	/* No PULL */
			};

		};


		fg_i2c {
			/* CLK, DATA */
			qcom,pins = <&gp 14>, <&gp 15>;
			qcom,num-grp-pins = <2>;
			qcom,pin-func = <0>;
			label = "fg_i2c";

			fg_i2c_active: fg_i2c_active {
				drive-strength = <2>;	/* 2 MA */
				bias-disable; /* No PULL */
			};

			fg_i2c_sleep: fg_i2c_sleep {
				drive-strength = <2>;	/* 2 MA */
				bias-disable; /* No PULL */
			};
		};

		chg_i2c {
			/* CLK, DATA */
			qcom,pins = <&gp 22>, <&gp 23>;
			qcom,num-grp-pins = <2>;
			qcom,pin-func = <0>;
			label = "chg_i2c";
			/* active state */
			chg_i2c_active: chg_i2c_active{
				drive-strength = <2>; /* 2 MA */
				bias-disable; /* No PULL */
			};
			/*suspended state */
			chg_i2c_sleep: chg_i2c_sleep {
				drive-strength = <2>; /* 2 MA */
				bias-disable; /* No PULL */
			};
		};

		charger_int_pin {
			qcom,pins = <&gp 62>;
			qcom,num-grp-pins = <1>;
			qcom,pin-func = <0>;
			label = "charger_int_gpio";
			charger_int_active: charger_int_active {
				drive-strength = <2>;
				bias-disable;
			};
		};

		fuel_int_pin {
			qcom,pins = <&gp 121>;
			qcom,num-grp-pins = <1>;
			qcom,pin-func = <0>;
			label = "fuel_int_gpio";
			fuel_int_active: fuel_int_active {
				drive-strength = <2>;
				bias-disable;		/* NO PULL */
			};
		};

		chg_en_pin {
			qcom,pins = <&gp 108>;
			qcom,num-grp-pins = <1>;
			qcom,pin-func = <0>;
			label = "chg_en_gpio";
			chg_en_active: chg_en_active {
				drive-strength = <2>;
				bias-disable;         /* No PULL */
			};
		};

		if_pmic_rst_pin {
			qcom,pins = <&gp 24>;
			qcom,num-grp-pins = <1>;
			qcom,pin-func = <0>;
			label = "if_pmic_rst_gpio";
			if_pmic_rst_active: if+pmic_rst_active {
				drive-strength = <2>;
				bias-disable;         /* No PULL */
			};
		};
	};
};
